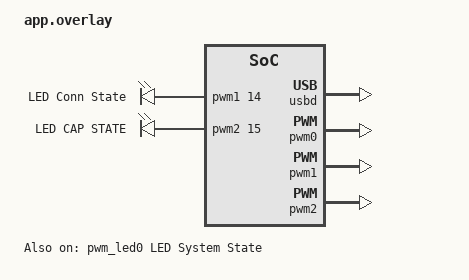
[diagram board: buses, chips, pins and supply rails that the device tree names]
/ {
	pwmleds1 {
		compatible = "pwm-leds";
		status = "okay";

		pwm_led1: led_pwm_1 {
			status = "okay";
			pwms = <&pwm1 14>;
			label = "LED Conn State";
		};
	};
};
/ {
	pwmleds2 {
		compatible = "pwm-leds";
		status = "okay";

		pwm_led2: led_pwm_2 {
			status = "okay";
			pwms = <&pwm2 15>;
			label = "LED CAP STATE";
		};
	};
};
&usbd {
	compatible = "nordic,nrf-usbd";
	status = "okay";
	num-bidir-endpoints = <0>;
	num-in-endpoints = <4>;
	num-out-endpoints = <2>;
	num-isoin-endpoints = <0>;
	num-isoout-endpoints = <0>;
};

&pwm0 {
	status = "okay";
	ch0-pin = <13>;
	ch0-inverted;
};

&pwm1 {
	status = "okay";
	ch0-pin = <14>;
	ch0-inverted;
};

&pwm2 {
	status = "okay";
	ch0-pin = <15>;
	ch0-inverted;
};
&pwm_led0 {
	status = "okay";
	pwms = <&pwm0 13>;
	label = "LED System State";
};

